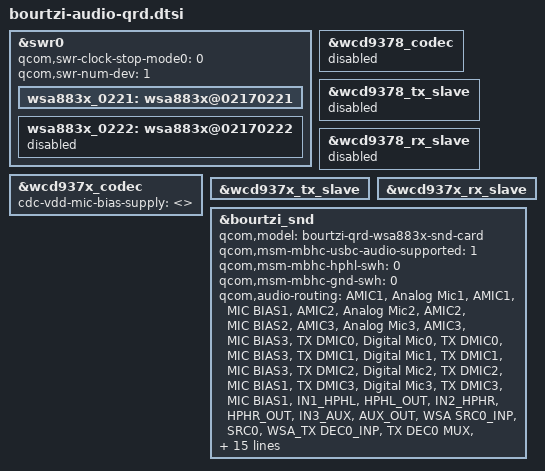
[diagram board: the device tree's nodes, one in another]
// SPDX-License-Identifier: BSD-3-Clause
/*
 * Copyright (c) Qualcomm Technologies, Inc. and/or its subsidiaries.
 */

#include "bourtzi-audio-overlay.dtsi"


&swr0 {
	qcom,swr-clock-stop-mode0 = <0>;
	qcom,swr-num-dev = <1>;

	wsa883x_0221: wsa883x@02170221 {
		status = "okay";
	};
	wsa883x_0222: wsa883x@02170222 {
		status = "disabled";
	};
};

&wcd9378_codec {
	status = "disabled";
};

&wcd9378_tx_slave {
	status = "disabled";
};

&wcd9378_rx_slave {
	status = "disabled";
};

&wcd937x_codec {
	status = "okay";

	cdc-vdd-mic-bias-supply = <>;
};

&wcd937x_tx_slave {
	status = "okay";
};

&wcd937x_rx_slave {
	status = "okay";
};

&bourtzi_snd {
	qcom,model = "bourtzi-qrd-wsa883x-snd-card";
	qcom,msm-mbhc-usbc-audio-supported = <1>;
	qcom,msm-mbhc-hphl-swh = <0>;
	qcom,msm-mbhc-gnd-swh = <0>;
	qcom,audio-routing =
			"AMIC1", "Analog Mic1",
			"AMIC1", "MIC BIAS1",
			"AMIC2", "Analog Mic2",
			"AMIC2", "MIC BIAS2",
			"AMIC3", "Analog Mic3",
			"AMIC3", "MIC BIAS3",
			"TX DMIC0", "Digital Mic0",
			"TX DMIC0", "MIC BIAS3",
			"TX DMIC1", "Digital Mic1",
			"TX DMIC1", "MIC BIAS3",
			"TX DMIC2", "Digital Mic2",
			"TX DMIC2", "MIC BIAS1",
			"TX DMIC3", "Digital Mic3",
			"TX DMIC3", "MIC BIAS1",
			"IN1_HPHL", "HPHL_OUT",
			"IN2_HPHR", "HPHR_OUT",
			"IN3_AUX", "AUX_OUT",
			"WSA SRC0_INP", "SRC0",
			"WSA_TX DEC0_INP", "TX DEC0 MUX",
			"RX_TX DEC0_INP", "TX DEC0 MUX",
			"RX_TX DEC1_INP", "TX DEC1 MUX",
			"RX_TX DEC2_INP", "TX DEC2 MUX",
			"RX_TX DEC3_INP", "TX DEC3 MUX",
			"SpkrLeft IN", "WSA_SPK1 OUT",
			"TX SWR_INPUT", "WCD_TX_OUTPUT",
			"VA SWR_INPUT", "VA_SWR_CLK",
			"VA SWR_INPUT", "WCD_TX_OUTPUT",
			"VA_AIF1 CAP", "VA_SWR_CLK",
			"VA_AIF2 CAP", "VA_SWR_CLK",
			"VA_AIF3 CAP", "VA_SWR_CLK";
	qcom,wsa-max-devs = <1>;
	fsa4480-i2c-handle = <&fsa4480>;
	qcom,msm-mbhc-hs-mic-max-threshold-mv = <1670>;
	asoc-codec = <&stub_codec>, <&lpass_cdc>,
					<&wcd937x_codec>, <&wsa883x_0221>;
	asoc-codec-names = "msm-stub-codec.1", "lpass-cdc",
					"wcd937x_codec", "wsa-codec1";
};
